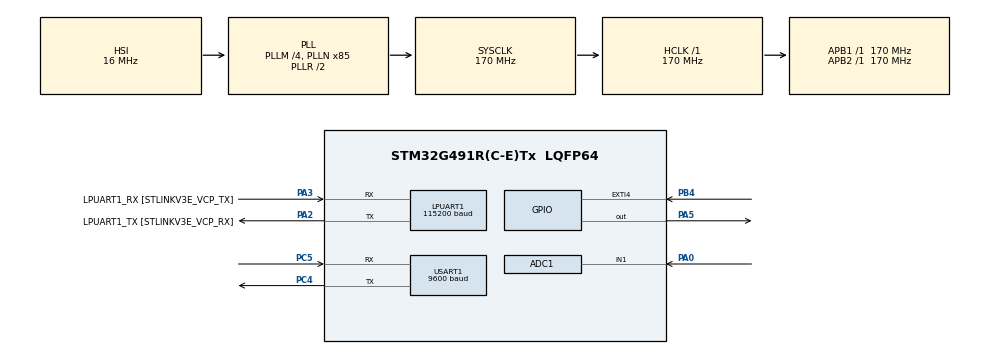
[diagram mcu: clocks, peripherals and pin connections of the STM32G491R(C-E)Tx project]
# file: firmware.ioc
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ADC1.Channel-0\#ChannelRegularConversion=ADC_CHANNEL_1
ADC1.NbrOfConversionFlag=1
ADC1.OffsetNumber-0\#ChannelRegularConversion=ADC_OFFSET_NONE
ADC1.Rank-0\#ChannelRegularConversion=1
ADC1.SamplingTime-0\#ChannelRegularConversion=ADC_SAMPLETIME_2CYCLES_5
ADC1.master=1
LPUART1.BaudRate=115200
Mcu.Family=STM32G4
Mcu.Name=STM32G491R(C-E)Tx
Mcu.Package=LQFP64
NVIC.EXTI4_IRQn=true\:0\:0\:false\:false\:true\:true\:true\:true
NVIC.LPUART1_IRQn=true\:0\:0\:false\:false\:true\:true\:true\:true
NVIC.PriorityGroup=NVIC_PRIORITYGROUP_4
NVIC.USART1_IRQn=true\:0\:0\:false\:false\:true\:true\:true\:true
PA0.Mode=IN1-Single-Ended
PA0.Signal=ADC1_IN1
PA13.GPIO_Label=T_SWDIO
PA13.Signal=SYS_JTMS-SWDIO
PA14.GPIO_Label=T_SWCLK
PA14.Signal=SYS_JTCK-SWCLK
PA2.GPIO_Label=LPUART1_TX [STLINKV3E_VCP_RX]
PA2.Mode=Asynchronous
PA2.Signal=LPUART1_TX
PA3.GPIO_Label=LPUART1_RX [STLINKV3E_VCP_TX]
PA3.Mode=Asynchronous
PA3.Signal=LPUART1_RX
PA5.Signal=GPIO_Output
PB3.GPIO_Label=T_SWO
PB3.Signal=SYS_JTDO-SWO
PB4.GPIO_PuPd=GPIO_PULLDOWN
PB4.Signal=GPXTI4
PC14-OSC32_IN.GPIO_Label=RCC_OSC32_IN
PC14-OSC32_IN.Signal=RCC_OSC32_IN
PC15-OSC32_OUT.GPIO_Label=RCC_OSC32_OUT
PC15-OSC32_OUT.Signal=RCC_OSC32_OUT
PC4.Mode=Asynchronous
PC4.Signal=USART1_TX
PC5.Mode=Asynchronous
PC5.Signal=USART1_RX
PF0-OSC_IN.GPIO_Label=RCC_OSC_IN
PF0-OSC_IN.Signal=RCC_OSC_IN
PF1-OSC_OUT.GPIO_Label=RCC_OSC_OUT
PF1-OSC_OUT.Signal=RCC_OSC_OUT
ProjectManager.HeapSize=0x200
ProjectManager.StackSize=0x400
ProjectManager.TargetToolchain=STM32CubeIDE
RCC.ADC12Freq_Value=170000000
RCC.ADC345Freq_Value=170000000
RCC.AHBFreq_Value=170000000
RCC.APB1Freq_Value=170000000
RCC.APB1TimFreq_Value=170000000
RCC.APB2Freq_Value=170000000
RCC.APB2TimFreq_Value=170000000
RCC.CortexFreq_Value=170000000
RCC.EXTERNAL_CLOCK_VALUE=12288000
RCC.HCLKFreq_Value=170000000
RCC.HSE_VALUE=24000000
RCC.HSI48_VALUE=48000000
RCC.HSI_VALUE=16000000
RCC.LSE_VALUE=32768
RCC.PLLM=RCC_PLLM_DIV4
RCC.PLLN=85
RCC.RTCClockSelection=RCC_RTCCLKSOURCE_LSE
RCC.SYSCLKFreq_VALUE=170000000
RCC.SYSCLKSource=RCC_SYSCLKSOURCE_PLLCLK
RCC.USBFreq_Value=48000000
RCC.VCOOutputFreq_Value=340000000
USART1.BaudRate=9600
USART1.VirtualMode-Asynchronous=VM_ASYNC
VP_SYS_VS_DBSignals.Mode=DisableDeadBatterySignals
VP_TIM2_VS_ClockSourceINT.Mode=Internal
board=NUCLEO-G491RE

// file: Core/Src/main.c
/* USER CODE BEGIN Header */
/**
  ******************************************************************************
  * @file           : main.c
  * @brief          : Main program body
  ******************************************************************************
  * @attention
  *
  * Copyright (c) 2026 STMicroelectronics.
  * All rights reserved.
  *
  * This software is licensed under terms that can be found in the LICENSE file
  * in the root directory of this software component.
  * If no LICENSE file comes with this software, it is provided AS-IS.
  *
  ******************************************************************************
  */
/* USER CODE END Header */
#include "main.h"

/* USER CODE BEGIN Includes */
#include "gridtwin_app.h"
/* USER CODE END Includes */

ADC_HandleTypeDef hadc1;

UART_HandleTypeDef hlpuart1;
UART_HandleTypeDef huart1;

TIM_HandleTypeDef htim2;

void SystemClock_Config(void);
static void MX_GPIO_Init(void);
static void MX_ADC1_Init(void);
static void MX_LPUART1_UART_Init(void);
static void MX_USART1_UART_Init(void);
static void MX_TIM2_Init(void);

int main(void)
{

  /* MCU Configuration--------------------------------------------------------*/

  /* Reset of all peripherals, Initializes the Flash interface and the Systick. */
  HAL_Init();

  /* Configure the system clock */
  SystemClock_Config();

  /* Initialize all configured peripherals */
  MX_GPIO_Init();
  MX_ADC1_Init();
  MX_LPUART1_UART_Init();
  MX_USART1_UART_Init();
  MX_TIM2_Init();
  /* USER CODE BEGIN 2 */
  app_init();
  /* USER CODE END 2 */

  /* Infinite loop */
  while (1)
  {

    /* USER CODE BEGIN 3 */
	  app_loop();
  }
  /* USER CODE END 3 */
}

void SystemClock_Config(void)
{
  RCC_OscInitTypeDef RCC_OscInitStruct = {0};
  RCC_ClkInitTypeDef RCC_ClkInitStruct = {0};

  /** Configure the main internal regulator output voltage
  */
  HAL_PWREx_ControlVoltageScaling(PWR_REGULATOR_VOLTAGE_SCALE1_BOOST);

  /** Initializes the RCC Oscillators according to the specified parameters
  * in the RCC_OscInitTypeDef structure.
  */
  RCC_OscInitStruct.OscillatorType = RCC_OSCILLATORTYPE_HSI;
  RCC_OscInitStruct.HSIState = RCC_HSI_ON;
  RCC_OscInitStruct.HSICalibrationValue = RCC_HSICALIBRATION_DEFAULT;
  RCC_OscInitStruct.PLL.PLLState = RCC_PLL_ON;
  RCC_OscInitStruct.PLL.PLLSource = RCC_PLLSOURCE_HSI;
  RCC_OscInitStruct.PLL.PLLM = RCC_PLLM_DIV4;
  RCC_OscInitStruct.PLL.PLLN = 85;
  RCC_OscInitStruct.PLL.PLLP = RCC_PLLP_DIV2;
  RCC_OscInitStruct.PLL.PLLQ = RCC_PLLQ_DIV2;
  RCC_OscInitStruct.PLL.PLLR = RCC_PLLR_DIV2;
  if (HAL_RCC_OscConfig(&RCC_OscInitStruct) != HAL_OK)
  {
    Error_Handler();
  }

  /** Initializes the CPU, AHB and APB buses clocks
  */
  RCC_ClkInitStruct.ClockType = RCC_CLOCKTYPE_HCLK|RCC_CLOCKTYPE_SYSCLK
                              |RCC_CLOCKTYPE_PCLK1|RCC_CLOCKTYPE_PCLK2;
  RCC_ClkInitStruct.SYSCLKSource = RCC_SYSCLKSOURCE_PLLCLK;
  RCC_ClkInitStruct.AHBCLKDivider = RCC_SYSCLK_DIV1;
  RCC_ClkInitStruct.APB1CLKDivider = RCC_HCLK_DIV1;
  RCC_ClkInitStruct.APB2CLKDivider = RCC_HCLK_DIV1;

  if (HAL_RCC_ClockConfig(&RCC_ClkInitStruct, FLASH_LATENCY_4) != HAL_OK)
  {
    Error_Handler();
  }
}

static void MX_ADC1_Init(void)
{

  ADC_MultiModeTypeDef multimode = {0};
  ADC_ChannelConfTypeDef sConfig = {0};

  /** Common config
  */
  hadc1.Instance = ADC1;
  hadc1.Init.ClockPrescaler = ADC_CLOCK_SYNC_PCLK_DIV4;
  hadc1.Init.Resolution = ADC_RESOLUTION_12B;
  hadc1.Init.DataAlign = ADC_DATAALIGN_RIGHT;
  hadc1.Init.GainCompensation = 0;
  hadc1.Init.ScanConvMode = ADC_SCAN_DISABLE;
  hadc1.Init.EOCSelection = ADC_EOC_SINGLE_CONV;
  hadc1.Init.LowPowerAutoWait = DISABLE;
  hadc1.Init.ContinuousConvMode = DISABLE;
  hadc1.Init.NbrOfConversion = 1;
  hadc1.Init.DiscontinuousConvMode = DISABLE;
  hadc1.Init.ExternalTrigConv = ADC_SOFTWARE_START;
  hadc1.Init.ExternalTrigConvEdge = ADC_EXTERNALTRIGCONVEDGE_NONE;
  hadc1.Init.DMAContinuousRequests = DISABLE;
  hadc1.Init.Overrun = ADC_OVR_DATA_PRESERVED;
  hadc1.Init.OversamplingMode = DISABLE;
  if (HAL_ADC_Init(&hadc1) != HAL_OK)
  {
    Error_Handler();
  }

  /** Configure the ADC multi-mode
  */
  multimode.Mode = ADC_MODE_INDEPENDENT;
  if (HAL_ADCEx_MultiModeConfigChannel(&hadc1, &multimode) != HAL_OK)
  {
    Error_Handler();
  }

  /** Configure Regular Channel
  */
  sConfig.Channel = ADC_CHANNEL_1;
  sConfig.Rank = ADC_REGULAR_RANK_1;
  sConfig.SamplingTime = ADC_SAMPLETIME_2CYCLES_5;
  sConfig.SingleDiff = ADC_SINGLE_ENDED;
  sConfig.OffsetNumber = ADC_OFFSET_NONE;
  sConfig.Offset = 0;
  if (HAL_ADC_ConfigChannel(&hadc1, &sConfig) != HAL_OK)
  {
    Error_Handler();
  }

}

static void MX_LPUART1_UART_Init(void)
{

  hlpuart1.Instance = LPUART1;
  hlpuart1.Init.BaudRate = 115200;
  hlpuart1.Init.WordLength = UART_WORDLENGTH_8B;
  hlpuart1.Init.StopBits = UART_STOPBITS_1;
  hlpuart1.Init.Parity = UART_PARITY_NONE;
  hlpuart1.Init.Mode = UART_MODE_TX_RX;
  hlpuart1.Init.HwFlowCtl = UART_HWCONTROL_NONE;
  hlpuart1.Init.OneBitSampling = UART_ONE_BIT_SAMPLE_DISABLE;
  hlpuart1.Init.ClockPrescaler = UART_PRESCALER_DIV1;
  hlpuart1.AdvancedInit.AdvFeatureInit = UART_ADVFEATURE_NO_INIT;
  if (HAL_UART_Init(&hlpuart1) != HAL_OK)
  {
    Error_Handler();
  }
  if (HAL_UARTEx_SetTxFifoThreshold(&hlpuart1, UART_TXFIFO_THRESHOLD_1_8) != HAL_OK)
  {
    Error_Handler();
  }
  if (HAL_UARTEx_SetRxFifoThreshold(&hlpuart1, UART_RXFIFO_THRESHOLD_1_8) != HAL_OK)
  {
    Error_Handler();
  }
  if (HAL_UARTEx_DisableFifoMode(&hlpuart1) != HAL_OK)
  {
    Error_Handler();
  }

}

static void MX_USART1_UART_Init(void)
{

  huart1.Instance = USART1;
  huart1.Init.BaudRate = 9600;
  huart1.Init.WordLength = UART_WORDLENGTH_8B;
  huart1.Init.StopBits = UART_STOPBITS_1;
  huart1.Init.Parity = UART_PARITY_NONE;
  huart1.Init.Mode = UART_MODE_TX_RX;
  huart1.Init.HwFlowCtl = UART_HWCONTROL_NONE;
  huart1.Init.OverSampling = UART_OVERSAMPLING_16;
  huart1.Init.OneBitSampling = UART_ONE_BIT_SAMPLE_DISABLE;
  huart1.Init.ClockPrescaler = UART_PRESCALER_DIV1;
  huart1.AdvancedInit.AdvFeatureInit = UART_ADVFEATURE_NO_INIT;
  if (HAL_UART_Init(&huart1) != HAL_OK)
  {
    Error_Handler();
  }
  if (HAL_UARTEx_SetTxFifoThreshold(&huart1, UART_TXFIFO_THRESHOLD_1_8) != HAL_OK)
  {
    Error_Handler();
  }
  if (HAL_UARTEx_SetRxFifoThreshold(&huart1, UART_RXFIFO_THRESHOLD_1_8) != HAL_OK)
  {
    Error_Handler();
  }
  if (HAL_UARTEx_DisableFifoMode(&huart1) != HAL_OK)
  {
    Error_Handler();
  }

}

static void MX_TIM2_Init(void)
{

  TIM_ClockConfigTypeDef sClockSourceConfig = {0};
  TIM_MasterConfigTypeDef sMasterConfig = {0};

  htim2.Instance = TIM2;
  htim2.Init.Prescaler = 0;
  htim2.Init.CounterMode = TIM_COUNTERMODE_UP;
  htim2.Init.Period = 4294967295;
  htim2.Init.ClockDivision = TIM_CLOCKDIVISION_DIV1;
  htim2.Init.AutoReloadPreload = TIM_AUTORELOAD_PRELOAD_DISABLE;
  if (HAL_TIM_Base_Init(&htim2) != HAL_OK)
  {
    Error_Handler();
  }
  sClockSourceConfig.ClockSource = TIM_CLOCKSOURCE_INTERNAL;
  if (HAL_TIM_ConfigClockSource(&htim2, &sClockSourceConfig) != HAL_OK)
  {
    Error_Handler();
  }
  sMasterConfig.MasterOutputTrigger = TIM_TRGO_RESET;
  sMasterConfig.MasterSlaveMode = TIM_MASTERSLAVEMODE_DISABLE;
  if (HAL_TIMEx_MasterConfigSynchronization(&htim2, &sMasterConfig) != HAL_OK)
  {
    Error_Handler();
  }

}

static void MX_GPIO_Init(void)
{
  GPIO_InitTypeDef GPIO_InitStruct = {0};

  /* GPIO Ports Clock Enable */
  __HAL_RCC_GPIOC_CLK_ENABLE();
  __HAL_RCC_GPIOF_CLK_ENABLE();
  __HAL_RCC_GPIOA_CLK_ENABLE();
  __HAL_RCC_GPIOB_CLK_ENABLE();

  /*Configure GPIO pin Output Level */
  HAL_GPIO_WritePin(GPIOA, GPIO_PIN_5, GPIO_PIN_RESET);

  /*Configure GPIO pin : PA5 */
  GPIO_InitStruct.Pin = GPIO_PIN_5;
  GPIO_InitStruct.Mode = GPIO_MODE_OUTPUT_PP;
  GPIO_InitStruct.Pull = GPIO_NOPULL;
  GPIO_InitStruct.Speed = GPIO_SPEED_FREQ_LOW;
  HAL_GPIO_Init(GPIOA, &GPIO_InitStruct);

  /*Configure GPIO pin : PB4 */
  GPIO_InitStruct.Pin = GPIO_PIN_4;
  GPIO_InitStruct.Mode = GPIO_MODE_IT_RISING;
  GPIO_InitStruct.Pull = GPIO_PULLDOWN;
  HAL_GPIO_Init(GPIOB, &GPIO_InitStruct);

  /* EXTI interrupt init*/
  HAL_NVIC_SetPriority(EXTI4_IRQn, 0, 0);
  HAL_NVIC_EnableIRQ(EXTI4_IRQn);

}

void Error_Handler(void)
{
  __disable_irq();
  while (1)
  {
  }
}
